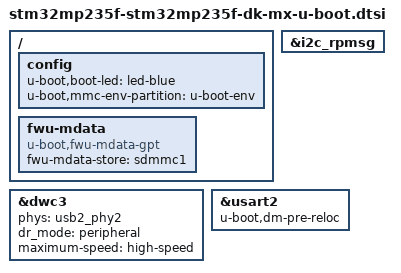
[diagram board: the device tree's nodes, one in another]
#include "stm32mp25-u-boot.dtsi"

/* USER CODE BEGIN includes */
/* USER CODE END includes */

/{

	/* USER CODE BEGIN root */

	config{
		u-boot,boot-led = "led-blue";
		u-boot,mmc-env-partition = "u-boot-env";
	};

	fwu-mdata{
		compatible = "u-boot,fwu-mdata-gpt";
		fwu-mdata-store = <&sdmmc1>;
	};
	/* USER CODE END root */
};

/* USER CODE BEGIN addons */

&dwc3{
	phys = <&usb2_phy2>;
	phy-names = "usb2-phy";
	dr_mode = "peripheral";
	maximum-speed = "high-speed";
	/delete-node/ port;
};

&i2c_rpmsg{
	/delete-node/ typec@35;
};

&usart2{
	u-boot,dm-pre-reloc;
};
/* USER CODE END addons */
